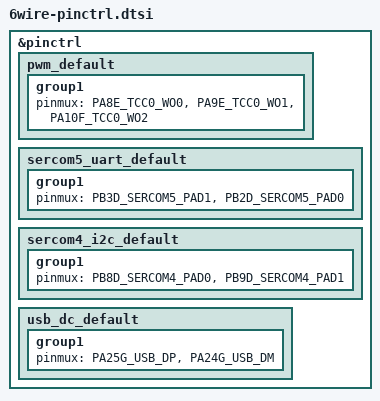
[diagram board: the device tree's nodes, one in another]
#include <dt-bindings/pinctrl/samd21-da1gXabcd-pinctrl.h>

&pinctrl {
    pwm_default: pwm_default {
        group1 {
            pinmux = <PA8E_TCC0_WO0>,
                     <PA9E_TCC0_WO1>,
                     <PA10F_TCC0_WO2>;
        };
    };

    sercom5_uart_default: sercom5_uart_default {
        group1 {
            pinmux = <PB3D_SERCOM5_PAD1>,
                     <PB2D_SERCOM5_PAD0>;
        };
    };

    sercom4_i2c_default: sercom4_i2c_default {
        group1 {
            pinmux = <PB8D_SERCOM4_PAD0>,
                     <PB9D_SERCOM4_PAD1>;
        };
    };

    usb_dc_default: usb_dc_default {
        group1 {
            pinmux = <PA25G_USB_DP>,
                     <PA24G_USB_DM>;
        };
    };
};
